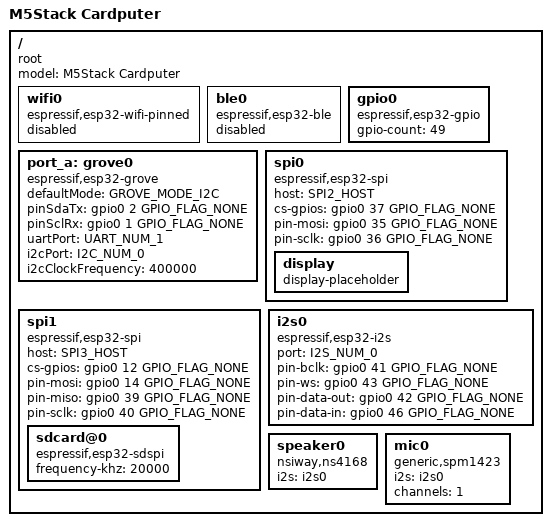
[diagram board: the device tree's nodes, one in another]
/dts-v1/;

#include <tactility/bindings/root.h>
#include <tactility/bindings/esp32_ble.h>
#include <tactility/bindings/esp32_wifi_pinned.h>
#include <tactility/bindings/esp32_gpio.h>
#include <tactility/bindings/esp32_grove.h>
#include <tactility/bindings/esp32_i2c.h>
#include <tactility/bindings/esp32_i2s.h>
#include <tactility/bindings/esp32_spi.h>
#include <tactility/bindings/esp32_uart.h>
#include <tactility/bindings/esp32_sdspi.h>
#include <tactility/bindings/display_placeholder.h>
#include <bindings/dummy_i2s_amp.h>
#include <bindings/pdm_mic.h>

// Reference: https://docs.m5stack.com/en/core/Cardputer
/ {
	compatible = "root";
	model = "M5Stack Cardputer";

	wifi0 {
		compatible = "espressif,esp32-wifi-pinned";
		status = "disabled";
	};

	ble0 {
		compatible = "espressif,esp32-ble";
		status = "disabled";
	};

	gpio0 {
		compatible = "espressif,esp32-gpio";
		gpio-count = <49>;
	};

	port_a: grove0 {
		compatible = "espressif,esp32-grove";
		defaultMode = <GROVE_MODE_I2C>;
		pinSdaTx = <&gpio0 2 GPIO_FLAG_NONE>;
		pinSclRx = <&gpio0 1 GPIO_FLAG_NONE>;
		uartPort = <UART_NUM_1>;
		i2cPort = <I2C_NUM_0>;
		i2cClockFrequency = <400000>;
	};

	spi0 {
		compatible = "espressif,esp32-spi";
		host = <SPI2_HOST>;
		cs-gpios = <&gpio0 37 GPIO_FLAG_NONE>;
		pin-mosi = <&gpio0 35 GPIO_FLAG_NONE>;
		pin-sclk = <&gpio0 36 GPIO_FLAG_NONE>;
	
		display {
			compatible = "display-placeholder";
		};
	};

	spi1 {
		compatible = "espressif,esp32-spi";
		host = <SPI3_HOST>;
		cs-gpios = <&gpio0 12 GPIO_FLAG_NONE>;
		pin-mosi = <&gpio0 14 GPIO_FLAG_NONE>;
		pin-miso = <&gpio0 39 GPIO_FLAG_NONE>;
		pin-sclk = <&gpio0 40 GPIO_FLAG_NONE>;
	
		sdcard@0 {
			compatible = "espressif,esp32-sdspi";
			frequency-khz = <20000>;
		};
	};

	// Speaker (std TX) and PDM mic (RX) share this single I2S controller. PDM RX is
	// hardware-restricted to I2S controller 0 on ESP32 targets, and per schematic the
	// mic's PDM CLK and the speaker's LRCLK both land on GPIO43 anyway -- splitting them
	// across two controllers (as M5Stack's own reference firmware does) isn't possible
	// here since Tactility's GPIO ownership model is exclusive-acquire-only (no pin
	// sharing), and two I2S controllers both declaring GPIO43 would have one fail to
	// start. Keeping both on one controller means only one acquire of GPIO43 happens;
	// audio_codec_data_if_i2s.c's data_set_fmt() already tears down and recreates the
	// channel on each codec open(), so opening one direction after the other naturally
	// reconfigures the shared port/pin -- speaker and mic still cannot be used
	// simultaneously, which matches the hardware reality.
	i2s0 {
		compatible = "espressif,esp32-i2s";
		port = <I2S_NUM_0>;
		pin-bclk = <&gpio0 41 GPIO_FLAG_NONE>;
		pin-ws = <&gpio0 43 GPIO_FLAG_NONE>;
		pin-data-out = <&gpio0 42 GPIO_FLAG_NONE>;
		pin-data-in = <&gpio0 46 GPIO_FLAG_NONE>;
	};

	speaker0 {
		compatible = "nsiway,ns4168";
		i2s = "i2s0";
	};

	mic0 {
		compatible = "generic,spm1423";
		i2s = "i2s0";
		channels = <1>;
	};
};
